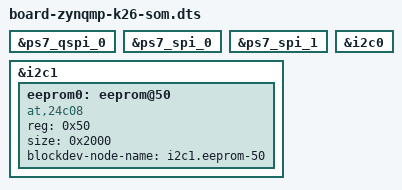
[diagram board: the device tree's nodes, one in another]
/*
 * ZynqMP K26 board device tree
 *
 * Copyright (c) 2021, Xilinx Inc
 * All rights reserved.
 *
 * Redistribution and use in source and binary forms, with or without
 * modification, are permitted provided that the following conditions are met:
 *     * Redistributions of source code must retain the above copyright
 *       notice, this list of conditions and the following disclaimer.
 *     * Redistributions in binary form must reproduce the above copyright
 *       notice, this list of conditions and the following disclaimer in the
 *       documentation and/or other materials provided with the distribution.
 *     * Neither the name of the <organization> nor the
 *       names of its contributors may be used to endorse or promote products
 *       derived from this software without specific prior written permission.
 *
 * THIS SOFTWARE IS PROVIDED BY THE COPYRIGHT HOLDERS AND CONTRIBUTORS "AS IS" AND
 * ANY EXPRESS OR IMPLIED WARRANTIES, INCLUDING, BUT NOT LIMITED TO, THE IMPLIED
 * WARRANTIES OF MERCHANTABILITY AND FITNESS FOR A PARTICULAR PURPOSE ARE
 * DISCLAIMED. IN NO EVENT SHALL <COPYRIGHT HOLDER> BE LIABLE FOR ANY
 * DIRECT, INDIRECT, INCIDENTAL, SPECIAL, EXEMPLARY, OR CONSEQUENTIAL DAMAGES
 * (INCLUDING, BUT NOT LIMITED TO, PROCUREMENT OF SUBSTITUTE GOODS OR SERVICES;
 * LOSS OF USE, DATA, OR PROFITS; OR BUSINESS INTERRUPTION) HOWEVER CAUSED AND
 * ON ANY THEORY OF LIABILITY, WHETHER IN CONTRACT, STRICT LIABILITY, OR TORT
 * (INCLUDING NEGLIGENCE OR OTHERWISE) ARISING IN ANY WAY OUT OF THE USE OF THIS
 * SOFTWARE, EVEN IF ADVISED OF THE POSSIBILITY OF SUCH DAMAGE.
 *
 * K26 has 64M QSPI flash and I2C EEPROM on address 0x50.
 * mtd drive index for qspi is 0 and eeproms need to use blockdev
 * ex:
 *
 * -blockdev node-name=i2c1.eeprom-50,filename=eeprom0.bin,driver=file
 *
 * For sd drives index is as below
 * sd1  -> 1
 * emmc -> 2
 */

#include "board-zynqmp-zcu102.dts"

&ps7_qspi_0 {
	/delete-node/ qspi_flash_ucs_ub@0;
};

&ps7_spi_0 {
	/delete-node/ spi0_flash0@0;
	/delete-node/ spi0_flash1@0;
	/delete-node/ spi0_flash2@0;
	/delete-node/ spi0_flash3@0;
};

&ps7_spi_1 {
	/delete-node/ spi1_flash0@0;
	/delete-node/ spi1_flash1@0;
	/delete-node/ spi1_flash2@0;
	/delete-node/ spi1_flash3@0;
};

&i2c0 {
	/delete-node/ tca6416@20;
	/delete-node/ tca6416@21;
	/delete-node/ i2cswitch@75;
};

&i2c1 {
	/delete-node/ i2cswitch@74;
	/delete-node/ i2cswitch@75;
	eeprom0: eeprom@50 {
		compatible = "at,24c08";
		reg = <0x50>;
		size = <0x2000>;
		blockdev-node-name = "i2c1.eeprom-50";
	};
};

